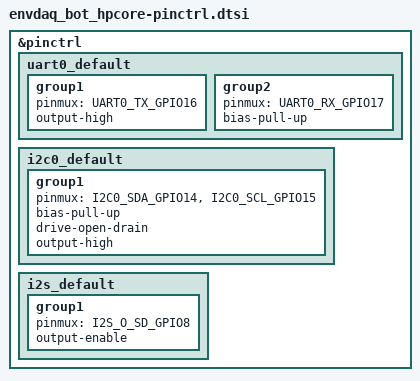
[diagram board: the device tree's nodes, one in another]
/*
 * Copyright (c) 2026 Yongci
 *
 * SPDX-License-Identifier: Apache-2.0
 */

#include <zephyr/dt-bindings/pinctrl/esp32c6-pinctrl.h>

&pinctrl {
	uart0_default: uart0_default {
		group1 {
			pinmux = <UART0_TX_GPIO16>;
			output-high;
		};

		group2 {
			pinmux = <UART0_RX_GPIO17>;
			bias-pull-up;
		};
	};

	i2c0_default: i2c0_default {
		group1 {
			pinmux = <I2C0_SDA_GPIO14>,
				 <I2C0_SCL_GPIO15>;
			bias-pull-up;
			drive-open-drain;
			output-high;
		};
	};

	i2s_default: i2s_default {
		group1 {
			pinmux = <I2S_O_SD_GPIO8>;
			output-enable;
		};
	};
};
